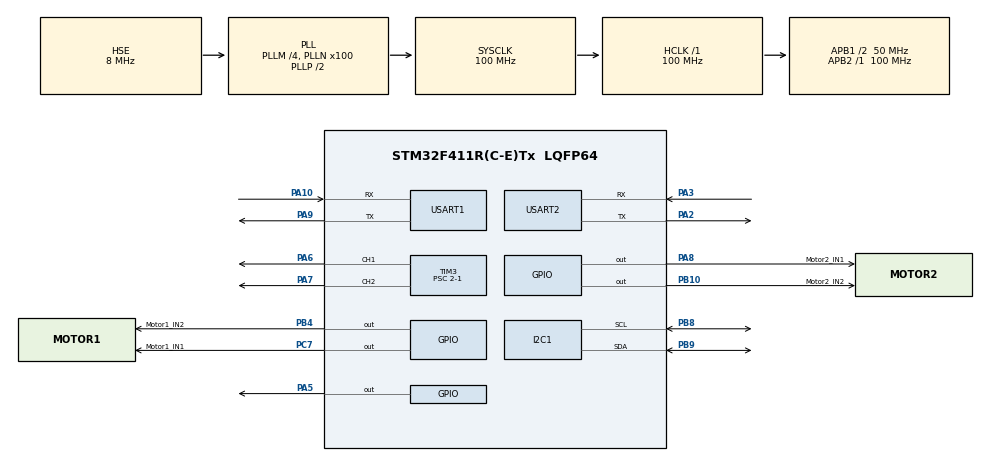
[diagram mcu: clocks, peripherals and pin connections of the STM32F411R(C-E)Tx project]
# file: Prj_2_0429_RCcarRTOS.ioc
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FREERTOS.Tasks01=defaultTask,0,128,StartDefaultTask,Default,NULL,Dynamic,NULL,NULL;listenerTask,-3,128,ListenerTask,Default,NULL,Dynamic,NULL,NULL;controllerTask,-3,128,ControllerTask,Default,NULL,Dynamic,NULL,NULL
Mcu.Family=STM32F4
Mcu.Name=STM32F411R(C-E)Tx
Mcu.Package=LQFP64
NVIC.PriorityGroup=NVIC_PRIORITYGROUP_4
NVIC.TIM1_TRG_COM_TIM11_IRQn=true\:15\:0\:false\:false\:true\:false\:false\:true\:true
NVIC.TimeBase=TIM1_TRG_COM_TIM11_IRQn
NVIC.TimeBaseIP=TIM11
NVIC.USART1_IRQn=true\:5\:0\:false\:false\:true\:true\:true\:true\:true
NVIC.USART2_IRQn=true\:5\:0\:false\:false\:true\:true\:true\:true\:true
PA10.Mode=Asynchronous
PA10.Signal=USART1_RX
PA13.Mode=Serial_Wire
PA13.Signal=SYS_JTMS-SWDIO
PA14.Mode=Serial_Wire
PA14.Signal=SYS_JTCK-SWCLK
PA2.Mode=Asynchronous
PA2.Signal=USART2_TX
PA3.Mode=Asynchronous
PA3.Signal=USART2_RX
PA5.Signal=GPIO_Output
PA6.Signal=S_TIM3_CH1
PA7.Signal=S_TIM3_CH2
PA8.GPIO_Label=Motor2_IN1
PA8.Signal=GPIO_Output
PA9.Mode=Asynchronous
PA9.Signal=USART1_TX
PB10.GPIO_Label=Motor2_IN2
PB10.Signal=GPIO_Output
PB4.GPIO_Label=Motor1_IN2
PB4.Signal=GPIO_Output
PB8.Mode=I2C
PB8.Signal=I2C1_SCL
PB9.Mode=I2C
PB9.Signal=I2C1_SDA
PC7.GPIO_Label=Motor1_IN1
PC7.Signal=GPIO_Output
PH0\ -\ OSC_IN.Mode=HSE-External-Oscillator
PH0\ -\ OSC_IN.Signal=RCC_OSC_IN
PH1\ -\ OSC_OUT.Mode=HSE-External-Oscillator
PH1\ -\ OSC_OUT.Signal=RCC_OSC_OUT
ProjectManager.HeapSize=0x200
ProjectManager.StackSize=0x400
ProjectManager.TargetToolchain=STM32CubeIDE
RCC.48MHZClocksFreq_Value=50000000
RCC.AHBFreq_Value=100000000
RCC.APB1CLKDivider=RCC_HCLK_DIV2
RCC.APB1Freq_Value=50000000
RCC.APB1TimFreq_Value=100000000
RCC.APB2Freq_Value=100000000
RCC.APB2TimFreq_Value=100000000
RCC.CortexFreq_Value=100000000
RCC.HCLKFreq_Value=100000000
RCC.HSE_VALUE=8000000
RCC.HSI_VALUE=16000000
RCC.LSE_VALUE=32768
RCC.PLLM=4
RCC.PLLN=100
RCC.PLLSourceVirtual=RCC_PLLSOURCE_HSE
RCC.SYSCLKFreq_VALUE=100000000
RCC.SYSCLKSource=RCC_SYSCLKSOURCE_PLLCLK
RCC.VCOOutputFreq_Value=200000000
SH.S_TIM3_CH1.0=TIM3_CH1,PWM Generation1 CH1
SH.S_TIM3_CH2.0=TIM3_CH2,PWM Generation2 CH2
TIM1.Prescaler=100-1
TIM3.Channel-PWM\ Generation1\ CH1=TIM_CHANNEL_1
TIM3.Channel-PWM\ Generation2\ CH2=TIM_CHANNEL_2
TIM3.Period=1000-1
TIM3.Prescaler=2-1
USART1.VirtualMode=VM_ASYNC
USART2.VirtualMode=VM_ASYNC
VP_FREERTOS_VS_CMSIS_V1.Mode=CMSIS_V1
VP_SYS_VS_tim11.Mode=TIM11
VP_TIM1_VS_ClockSourceINT.Mode=Internal
VP_TIM2_VS_ClockSourceINT.Mode=Internal
VP_TIM3_VS_ClockSourceINT.Mode=Internal
board=custom

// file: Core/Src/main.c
/* USER CODE BEGIN Header */
/**
  ******************************************************************************
  * @file           : main.c
  * @brief          : Main program body
  ******************************************************************************
  * @attention
  *
  * Copyright (c) 2024 STMicroelectronics.
  * All rights reserved.
  *
  * This software is licensed under terms that can be found in the LICENSE file
  * in the root directory of this software component.
  * If no LICENSE file comes with this software, it is provided AS-IS.
  *
  ******************************************************************************
  */
/* USER CODE END Header */
#include "main.h"
#include "cmsis_os.h"

/* USER CODE BEGIN Includes */
#include "../AP/AP_Main.h"
/* USER CODE END Includes */

I2C_HandleTypeDef hi2c1;

TIM_HandleTypeDef htim1;
TIM_HandleTypeDef htim2;
TIM_HandleTypeDef htim3;

UART_HandleTypeDef huart1;
UART_HandleTypeDef huart2;

osThreadId defaultTaskHandle;
osThreadId listenerTaskHandle;
osThreadId controllerTaskHandle;

void SystemClock_Config(void);
static void MX_GPIO_Init(void);
static void MX_I2C1_Init(void);
static void MX_TIM3_Init(void);
static void MX_USART2_UART_Init(void);
static void MX_TIM1_Init(void);
static void MX_TIM2_Init(void);
static void MX_USART1_UART_Init(void);
void StartDefaultTask(void const * argument);
void ListenerTask(void const * argument);
void ControllerTask(void const * argument);

/* USER CODE BEGIN 0 */
//uint8_t rcvData;
//void HAL_UART_RxCpltCallback(UART_HandleTypeDef *huart)
//{
//	if (huart->Instance == USART2)
//	{
//		Listener_ISR_Process(rcvData);
//		HAL_UART_Receive_IT(&huart2, &rcvData, 1);
//		HAL_UART_Transmit(&huart2, &rcvData, 1, 1000);
//	}
//}
/* USER CODE END 0 */

int main(void)
{

  /* MCU Configuration--------------------------------------------------------*/

  /* Reset of all peripherals, Initializes the Flash interface and the Systick. */
  HAL_Init();

  /* Configure the system clock */
  SystemClock_Config();

  /* Initialize all configured peripherals */
  MX_GPIO_Init();
  MX_I2C1_Init();
  MX_TIM3_Init();
  MX_USART2_UART_Init();
  MX_TIM1_Init();
  MX_TIM2_Init();
  MX_USART1_UART_Init();
  /* USER CODE BEGIN 2 */

  //AP_Main_init(&huart2, &htim3, &htim1, &htim2, &htim3);

  /* USER CODE END 2 */

  /* Create the thread(s) */
  /* definition and creation of defaultTask */
  osThreadDef(defaultTask, StartDefaultTask, osPriorityNormal, 0, 128);
  defaultTaskHandle = osThreadCreate(osThread(defaultTask), NULL);

  /* definition and creation of listenerTask */
  osThreadDef(listenerTask, ListenerTask, osPriorityIdle, 0, 128);
  listenerTaskHandle = osThreadCreate(osThread(listenerTask), NULL);

  /* definition and creation of controllerTask */
  osThreadDef(controllerTask, ControllerTask, osPriorityIdle, 0, 128);
  controllerTaskHandle = osThreadCreate(osThread(controllerTask), NULL);

  /* Start scheduler */
  osKernelStart();

  /* We should never get here as control is now taken by the scheduler */

  /* Infinite loop */
  /* USER CODE BEGIN WHILE */
  while (1)
  {
  	AP_Main_execute();
    /* USER CODE END WHILE */

  }
}

void SystemClock_Config(void)
{
  RCC_OscInitTypeDef RCC_OscInitStruct = {0};
  RCC_ClkInitTypeDef RCC_ClkInitStruct = {0};

  /** Configure the main internal regulator output voltage
  */
  __HAL_RCC_PWR_CLK_ENABLE();
  __HAL_PWR_VOLTAGESCALING_CONFIG(PWR_REGULATOR_VOLTAGE_SCALE1);

  /** Initializes the RCC Oscillators according to the specified parameters
  * in the RCC_OscInitTypeDef structure.
  */
  RCC_OscInitStruct.OscillatorType = RCC_OSCILLATORTYPE_HSE;
  RCC_OscInitStruct.HSEState = RCC_HSE_ON;
  RCC_OscInitStruct.PLL.PLLState = RCC_PLL_ON;
  RCC_OscInitStruct.PLL.PLLSource = RCC_PLLSOURCE_HSE;
  RCC_OscInitStruct.PLL.PLLM = 4;
  RCC_OscInitStruct.PLL.PLLN = 100;
  RCC_OscInitStruct.PLL.PLLP = RCC_PLLP_DIV2;
  RCC_OscInitStruct.PLL.PLLQ = 4;
  if (HAL_RCC_OscConfig(&RCC_OscInitStruct) != HAL_OK)
  {
    Error_Handler();
  }

  /** Initializes the CPU, AHB and APB buses clocks
  */
  RCC_ClkInitStruct.ClockType = RCC_CLOCKTYPE_HCLK|RCC_CLOCKTYPE_SYSCLK
                              |RCC_CLOCKTYPE_PCLK1|RCC_CLOCKTYPE_PCLK2;
  RCC_ClkInitStruct.SYSCLKSource = RCC_SYSCLKSOURCE_PLLCLK;
  RCC_ClkInitStruct.AHBCLKDivider = RCC_SYSCLK_DIV1;
  RCC_ClkInitStruct.APB1CLKDivider = RCC_HCLK_DIV2;
  RCC_ClkInitStruct.APB2CLKDivider = RCC_HCLK_DIV1;

  if (HAL_RCC_ClockConfig(&RCC_ClkInitStruct, FLASH_LATENCY_3) != HAL_OK)
  {
    Error_Handler();
  }
}

static void MX_I2C1_Init(void)
{

  hi2c1.Instance = I2C1;
  hi2c1.Init.ClockSpeed = 100000;
  hi2c1.Init.DutyCycle = I2C_DUTYCYCLE_2;
  hi2c1.Init.OwnAddress1 = 0;
  hi2c1.Init.AddressingMode = I2C_ADDRESSINGMODE_7BIT;
  hi2c1.Init.DualAddressMode = I2C_DUALADDRESS_DISABLE;
  hi2c1.Init.OwnAddress2 = 0;
  hi2c1.Init.GeneralCallMode = I2C_GENERALCALL_DISABLE;
  hi2c1.Init.NoStretchMode = I2C_NOSTRETCH_DISABLE;
  if (HAL_I2C_Init(&hi2c1) != HAL_OK)
  {
    Error_Handler();
  }

}

static void MX_TIM1_Init(void)
{

  TIM_ClockConfigTypeDef sClockSourceConfig = {0};
  TIM_MasterConfigTypeDef sMasterConfig = {0};

  htim1.Instance = TIM1;
  htim1.Init.Prescaler = 100-1;
  htim1.Init.CounterMode = TIM_COUNTERMODE_UP;
  htim1.Init.Period = 65535;
  htim1.Init.ClockDivision = TIM_CLOCKDIVISION_DIV1;
  htim1.Init.RepetitionCounter = 0;
  htim1.Init.AutoReloadPreload = TIM_AUTORELOAD_PRELOAD_DISABLE;
  if (HAL_TIM_Base_Init(&htim1) != HAL_OK)
  {
    Error_Handler();
  }
  sClockSourceConfig.ClockSource = TIM_CLOCKSOURCE_INTERNAL;
  if (HAL_TIM_ConfigClockSource(&htim1, &sClockSourceConfig) != HAL_OK)
  {
    Error_Handler();
  }
  sMasterConfig.MasterOutputTrigger = TIM_TRGO_RESET;
  sMasterConfig.MasterSlaveMode = TIM_MASTERSLAVEMODE_DISABLE;
  if (HAL_TIMEx_MasterConfigSynchronization(&htim1, &sMasterConfig) != HAL_OK)
  {
    Error_Handler();
  }

}

static void MX_TIM2_Init(void)
{

  TIM_ClockConfigTypeDef sClockSourceConfig = {0};
  TIM_MasterConfigTypeDef sMasterConfig = {0};

  htim2.Instance = TIM2;
  htim2.Init.Prescaler = 0;
  htim2.Init.CounterMode = TIM_COUNTERMODE_UP;
  htim2.Init.Period = 4294967295;
  htim2.Init.ClockDivision = TIM_CLOCKDIVISION_DIV1;
  htim2.Init.AutoReloadPreload = TIM_AUTORELOAD_PRELOAD_DISABLE;
  if (HAL_TIM_Base_Init(&htim2) != HAL_OK)
  {
    Error_Handler();
  }
  sClockSourceConfig.ClockSource = TIM_CLOCKSOURCE_INTERNAL;
  if (HAL_TIM_ConfigClockSource(&htim2, &sClockSourceConfig) != HAL_OK)
  {
    Error_Handler();
  }
  sMasterConfig.MasterOutputTrigger = TIM_TRGO_RESET;
  sMasterConfig.MasterSlaveMode = TIM_MASTERSLAVEMODE_DISABLE;
  if (HAL_TIMEx_MasterConfigSynchronization(&htim2, &sMasterConfig) != HAL_OK)
  {
    Error_Handler();
  }

}

static void MX_TIM3_Init(void)
{

  TIM_ClockConfigTypeDef sClockSourceConfig = {0};
  TIM_MasterConfigTypeDef sMasterConfig = {0};
  TIM_OC_InitTypeDef sConfigOC = {0};

  htim3.Instance = TIM3;
  htim3.Init.Prescaler = 2-1;
  htim3.Init.CounterMode = TIM_COUNTERMODE_UP;
  htim3.Init.Period = 1000-1;
  htim3.Init.ClockDivision = TIM_CLOCKDIVISION_DIV1;
  htim3.Init.AutoReloadPreload = TIM_AUTORELOAD_PRELOAD_DISABLE;
  if (HAL_TIM_Base_Init(&htim3) != HAL_OK)
  {
    Error_Handler();
  }
  sClockSourceConfig.ClockSource = TIM_CLOCKSOURCE_INTERNAL;
  if (HAL_TIM_ConfigClockSource(&htim3, &sClockSourceConfig) != HAL_OK)
  {
    Error_Handler();
  }
  if (HAL_TIM_PWM_Init(&htim3) != HAL_OK)
  {
    Error_Handler();
  }
  sMasterConfig.MasterOutputTrigger = TIM_TRGO_RESET;
  sMasterConfig.MasterSlaveMode = TIM_MASTERSLAVEMODE_DISABLE;
  if (HAL_TIMEx_MasterConfigSynchronization(&htim3, &sMasterConfig) != HAL_OK)
  {
    Error_Handler();
  }
  sConfigOC.OCMode = TIM_OCMODE_PWM1;
  sConfigOC.Pulse = 0;
  sConfigOC.OCPolarity = TIM_OCPOLARITY_HIGH;
  sConfigOC.OCFastMode = TIM_OCFAST_DISABLE;
  if (HAL_TIM_PWM_ConfigChannel(&htim3, &sConfigOC, TIM_CHANNEL_1) != HAL_OK)
  {
    Error_Handler();
  }
  if (HAL_TIM_PWM_ConfigChannel(&htim3, &sConfigOC, TIM_CHANNEL_2) != HAL_OK)
  {
    Error_Handler();
  }
  HAL_TIM_MspPostInit(&htim3);

}

static void MX_USART1_UART_Init(void)
{

  huart1.Instance = USART1;
  huart1.Init.BaudRate = 115200;
  huart1.Init.WordLength = UART_WORDLENGTH_8B;
  huart1.Init.StopBits = UART_STOPBITS_1;
  huart1.Init.Parity = UART_PARITY_NONE;
  huart1.Init.Mode = UART_MODE_TX_RX;
  huart1.Init.HwFlowCtl = UART_HWCONTROL_NONE;
  huart1.Init.OverSampling = UART_OVERSAMPLING_16;
  if (HAL_UART_Init(&huart1) != HAL_OK)
  {
    Error_Handler();
  }

}

static void MX_USART2_UART_Init(void)
{

  huart2.Instance = USART2;
  huart2.Init.BaudRate = 115200;
  huart2.Init.WordLength = UART_WORDLENGTH_8B;
  huart2.Init.StopBits = UART_STOPBITS_1;
  huart2.Init.Parity = UART_PARITY_NONE;
  huart2.Init.Mode = UART_MODE_TX_RX;
  huart2.Init.HwFlowCtl = UART_HWCONTROL_NONE;
  huart2.Init.OverSampling = UART_OVERSAMPLING_16;
  if (HAL_UART_Init(&huart2) != HAL_OK)
  {
    Error_Handler();
  }

}

static void MX_GPIO_Init(void)
{
  GPIO_InitTypeDef GPIO_InitStruct = {0};

  /* GPIO Ports Clock Enable */
  __HAL_RCC_GPIOH_CLK_ENABLE();
  __HAL_RCC_GPIOA_CLK_ENABLE();
  __HAL_RCC_GPIOB_CLK_ENABLE();
  __HAL_RCC_GPIOC_CLK_ENABLE();

  /*Configure GPIO pin Output Level */
  HAL_GPIO_WritePin(GPIOA, GPIO_PIN_5|Motor2_IN1_Pin, GPIO_PIN_RESET);

  /*Configure GPIO pin Output Level */
  HAL_GPIO_WritePin(GPIOB, Motor2_IN2_Pin|Motor1_IN2_Pin, GPIO_PIN_RESET);

  /*Configure GPIO pin Output Level */
  HAL_GPIO_WritePin(Motor1_IN1_GPIO_Port, Motor1_IN1_Pin, GPIO_PIN_RESET);

  /*Configure GPIO pins : PA5 Motor2_IN1_Pin */
  GPIO_InitStruct.Pin = GPIO_PIN_5|Motor2_IN1_Pin;
  GPIO_InitStruct.Mode = GPIO_MODE_OUTPUT_PP;
  GPIO_InitStruct.Pull = GPIO_NOPULL;
  GPIO_InitStruct.Speed = GPIO_SPEED_FREQ_LOW;
  HAL_GPIO_Init(GPIOA, &GPIO_InitStruct);

  /*Configure GPIO pins : Motor2_IN2_Pin Motor1_IN2_Pin */
  GPIO_InitStruct.Pin = Motor2_IN2_Pin|Motor1_IN2_Pin;
  GPIO_InitStruct.Mode = GPIO_MODE_OUTPUT_PP;
  GPIO_InitStruct.Pull = GPIO_NOPULL;
  GPIO_InitStruct.Speed = GPIO_SPEED_FREQ_LOW;
  HAL_GPIO_Init(GPIOB, &GPIO_InitStruct);

  /*Configure GPIO pin : Motor1_IN1_Pin */
  GPIO_InitStruct.Pin = Motor1_IN1_Pin;
  GPIO_InitStruct.Mode = GPIO_MODE_OUTPUT_PP;
  GPIO_InitStruct.Pull = GPIO_NOPULL;
  GPIO_InitStruct.Speed = GPIO_SPEED_FREQ_LOW;
  HAL_GPIO_Init(Motor1_IN1_GPIO_Port, &GPIO_InitStruct);

}

/* USER CODE BEGIN 4 */
uint8_t rcvData;

void HAL_UART_RxCpltCallback(UART_HandleTypeDef *huart)
{
	if (huart->Instance == USART2)
	{
		Listener_ISR_Process(rcvData);
		HAL_UART_Transmit(Model_getHandler()->myHuart, &rcvData, 1, 100);
		HAL_UART_Receive_IT(Model_getHandler()->myHuart, &rcvData, 1);
	}
}
/* USER CODE END 4 */

void StartDefaultTask(void const * argument)
{
  /* USER CODE BEGIN 5 */
  AP_Main_init(&huart2, &htim3, &htim1, &htim2, &htim3);
	HAL_UART_Receive_IT(Model_getHandler()->myHuart, &rcvData, 1);
  /* Infinite loop */
  for(;;)
  {
  	HAL_GPIO_TogglePin(GPIOA, GPIO_PIN_5);
    osDelay(100);
  }
  /* USER CODE END 5 */
}

void ListenerTask(void const * argument)
{
  /* USER CODE BEGIN ListenerTask */
  /* Infinite loop */
  for(;;)
  {
  	Listener_CarMode_EventCheck();
    osDelay(1);
  }
  /* USER CODE END ListenerTask */
}

void ControllerTask(void const * argument)
{
  /* USER CODE BEGIN ControllerTask */
  /* Infinite loop */
  for(;;)
  {
  	Controller_Car_execute();
    osDelay(1);
  }
  /* USER CODE END ControllerTask */
}

void HAL_TIM_PeriodElapsedCallback(TIM_HandleTypeDef *htim)
{
  if (htim->Instance == TIM11) {
    HAL_IncTick();
  }
}

void Error_Handler(void)
{
  __disable_irq();
  while (1)
  {
  }
}
